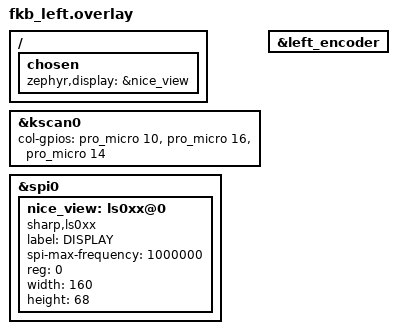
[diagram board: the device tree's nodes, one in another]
#include "fkb.dtsi"

&kscan0 {
       col-gpios
            = <&pro_micro 10 GPIO_ACTIVE_HIGH>
            , <&pro_micro 16 GPIO_ACTIVE_HIGH>
            , <&pro_micro 14 GPIO_ACTIVE_HIGH>
            ;
    };

&left_encoder {
	status = "okay";
};

&spi0 {
    status = "okay";
    nice_view: ls0xx@0 {
        compatible = "sharp,ls0xx";
        label = "DISPLAY";
        spi-max-frequency = <1000000>;
        reg = <0>;
        width = <160>;
        height = <68>;
    };
};

/ {
    chosen {
        zephyr,display = &nice_view;
    };
};
